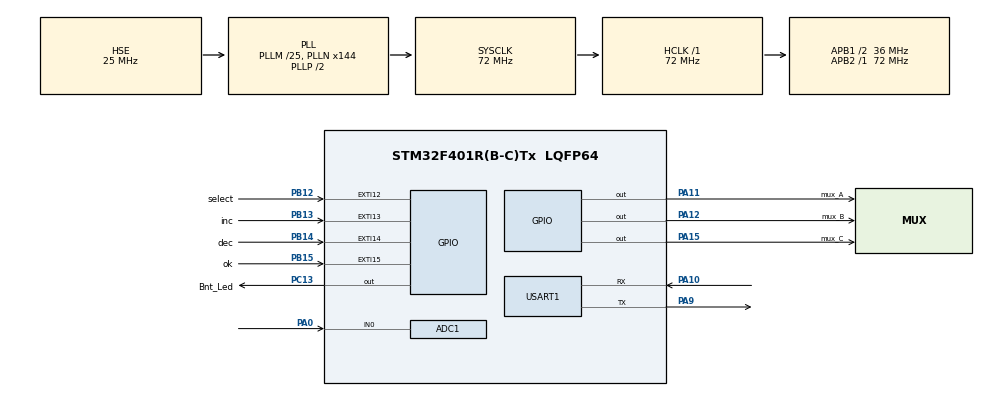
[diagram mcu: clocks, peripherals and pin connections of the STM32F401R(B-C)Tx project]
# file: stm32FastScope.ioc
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ADC1.Channel-2\#ChannelRegularConversion=ADC_CHANNEL_0
ADC1.Channel-3\#ChannelInjectedConversion=ADC_CHANNEL_0
ADC1.DMAContinuousRequests=ENABLE
ADC1.ExternalTrigConv=ADC_EXTERNALTRIGCONV_T3_TRGO
ADC1.InjNumberOfConversion=1
ADC1.InjectedOffset-3\#ChannelInjectedConversion=0
ADC1.InjectedRank-3\#ChannelInjectedConversion=1
ADC1.NbrOfConversion=1
ADC1.NbrOfConversionFlag=1
ADC1.Rank-2\#ChannelRegularConversion=1
ADC1.Resolution=ADC_RESOLUTION_8B
ADC1.SamplingTime-2\#ChannelRegularConversion=ADC_SAMPLETIME_3CYCLES
ADC1.SamplingTime-3\#ChannelInjectedConversion=ADC_SAMPLETIME_3CYCLES
ADC1.master=1
Dma.ADC1.0.Direction=DMA_PERIPH_TO_MEMORY
Dma.ADC1.0.FIFOMode=DMA_FIFOMODE_DISABLE
Dma.ADC1.0.Instance=DMA2_Stream0
Dma.ADC1.0.MemDataAlignment=DMA_MDATAALIGN_HALFWORD
Dma.ADC1.0.MemInc=DMA_MINC_ENABLE
Dma.ADC1.0.Mode=DMA_NORMAL
Dma.ADC1.0.PeriphDataAlignment=DMA_PDATAALIGN_HALFWORD
Dma.ADC1.0.PeriphInc=DMA_PINC_DISABLE
Dma.ADC1.0.Priority=DMA_PRIORITY_LOW
Dma.Request0=ADC1
Dma.Request1=USART1_TX
Dma.Request2=USART1_RX
Dma.USART1_RX.2.Direction=DMA_PERIPH_TO_MEMORY
Dma.USART1_RX.2.FIFOMode=DMA_FIFOMODE_DISABLE
Dma.USART1_RX.2.Instance=DMA2_Stream2
Dma.USART1_RX.2.MemDataAlignment=DMA_MDATAALIGN_BYTE
Dma.USART1_RX.2.MemInc=DMA_MINC_ENABLE
Dma.USART1_RX.2.Mode=DMA_CIRCULAR
Dma.USART1_RX.2.PeriphDataAlignment=DMA_PDATAALIGN_BYTE
Dma.USART1_RX.2.PeriphInc=DMA_PINC_DISABLE
Dma.USART1_RX.2.Priority=DMA_PRIORITY_LOW
Dma.USART1_TX.1.Direction=DMA_MEMORY_TO_PERIPH
Dma.USART1_TX.1.FIFOMode=DMA_FIFOMODE_DISABLE
Dma.USART1_TX.1.Instance=DMA2_Stream7
Dma.USART1_TX.1.MemDataAlignment=DMA_MDATAALIGN_BYTE
Dma.USART1_TX.1.MemInc=DMA_MINC_ENABLE
Dma.USART1_TX.1.Mode=DMA_CIRCULAR
Dma.USART1_TX.1.PeriphDataAlignment=DMA_PDATAALIGN_BYTE
Dma.USART1_TX.1.PeriphInc=DMA_PINC_DISABLE
Dma.USART1_TX.1.Priority=DMA_PRIORITY_LOW
Mcu.Family=STM32F4
Mcu.Name=STM32F401R(B-C)Tx
Mcu.Package=LQFP64
Mcu.UserConstants=Adc_prescaler,1;Adc_stop,1050
NVIC.DMA2_Stream0_IRQn=true\:0\:0\:false\:false\:true\:false\:true\:true
NVIC.DMA2_Stream2_IRQn=true\:0\:0\:false\:false\:true\:false\:true\:true
NVIC.DMA2_Stream7_IRQn=true\:0\:0\:false\:false\:true\:false\:true\:true
NVIC.EXTI15_10_IRQn=true\:0\:0\:false\:false\:true\:true\:true\:true
NVIC.PriorityGroup=NVIC_PRIORITYGROUP_4
NVIC.TIM3_IRQn=true\:0\:0\:false\:false\:true\:true\:true\:true
NVIC.TIM4_IRQn=true\:0\:0\:false\:false\:true\:true\:true\:true
PA0-WKUP.Signal=ADCx_IN0
PA10.Mode=Asynchronous
PA10.Signal=USART1_RX
PA11.GPIO_Label=mux_A
PA11.GPIO_PuPd=GPIO_PULLUP
PA11.Signal=GPIO_Output
PA12.GPIO_Label=mux_B
PA12.GPIO_PuPd=GPIO_PULLUP
PA12.Signal=GPIO_Output
PA15.GPIO_Label=mux_C
PA15.GPIO_PuPd=GPIO_PULLUP
PA15.Signal=GPIO_Output
PA9.Mode=Asynchronous
PA9.Signal=USART1_TX
PB12.GPIO_Label=select
PB12.GPIO_PuPd=GPIO_PULLUP
PB12.Signal=GPXTI12
PB13.GPIO_Label=inc
PB13.GPIO_PuPd=GPIO_PULLUP
PB13.Signal=GPXTI13
PB14.GPIO_Label=dec
PB14.GPIO_PuPd=GPIO_PULLUP
PB14.Signal=GPXTI14
PB15.GPIO_Label=ok
PB15.GPIO_PuPd=GPIO_PULLUP
PB15.Signal=GPXTI15
PC13-ANTI_TAMP.GPIO_Label=Bnt_Led
PC13-ANTI_TAMP.Signal=GPIO_Output
PH0\ -\ OSC_IN.Mode=HSE-External-Oscillator
PH0\ -\ OSC_IN.Signal=RCC_OSC_IN
PH1\ -\ OSC_OUT.Mode=HSE-External-Oscillator
PH1\ -\ OSC_OUT.Signal=RCC_OSC_OUT
ProjectManager.HeapSize=0x200
ProjectManager.StackSize=0x400
ProjectManager.TargetToolchain=STM32CubeIDE
RCC.48MHZClocksFreq_Value=36000000
RCC.AHBFreq_Value=72000000
RCC.APB1CLKDivider=RCC_HCLK_DIV2
RCC.APB1Freq_Value=36000000
RCC.APB1TimFreq_Value=72000000
RCC.APB2Freq_Value=72000000
RCC.APB2TimFreq_Value=72000000
RCC.CortexFreq_Value=72000000
RCC.HCLKFreq_Value=72000000
RCC.HSE_VALUE=25000000
RCC.HSI_VALUE=16000000
RCC.LSE_VALUE=32768
RCC.PLLM=25
RCC.PLLN=144
RCC.PLLSourceVirtual=RCC_PLLSOURCE_HSE
RCC.SYSCLKFreq_VALUE=72000000
RCC.SYSCLKSource=RCC_SYSCLKSOURCE_PLLCLK
RCC.VCOOutputFreq_Value=144000000
SH.ADCx_IN0.0=ADC1_IN0,IN0
TIM3.AutoReloadPreload=TIM_AUTORELOAD_PRELOAD_ENABLE
TIM3.ClockDivision=TIM_CLOCKDIVISION_DIV1
TIM3.Period=Adc_stop
TIM3.Prescaler=Adc_prescaler
TIM3.TIM_MasterOutputTrigger=TIM_TRGO_UPDATE
TIM3.TIM_MasterSlaveMode=TIM_MASTERSLAVEMODE_ENABLE
TIM4.Period=250
TIM4.Prescaler=20499
USART1.VirtualMode=VM_ASYNC
VP_TIM3_VS_ClockSourceINT.Mode=Internal
VP_TIM4_VS_ClockSourceINT.Mode=Internal
board=custom

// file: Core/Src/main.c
/* USER CODE BEGIN Header */
/**
 ******************************************************************************
 * @file           : main.c
 * @brief          : Main program body
 ******************************************************************************
 * @attention
 *
 * Copyright (c) 2023 STMicroelectronics.
 * All rights reserved.
 *
 * This software is licensed under terms that can be found in the LICENSE file
 * in the root directory of this software component.
 * If no LICENSE file comes with this software, it is provided AS-IS.
 *
 ******************************************************************************
 */
/* USER CODE END Header */
#include "main.h"

/* USER CODE BEGIN Includes */
//#include "defines.h"
/* USER CODE END Includes */

ADC_HandleTypeDef hadc1;
DMA_HandleTypeDef hdma_adc1;

TIM_HandleTypeDef htim3;
TIM_HandleTypeDef htim4;

UART_HandleTypeDef huart1;
DMA_HandleTypeDef hdma_usart1_tx;
DMA_HandleTypeDef hdma_usart1_rx;

void SystemClock_Config(void);
static void MX_GPIO_Init(void);
static void MX_DMA_Init(void);
static void MX_ADC1_Init(void);
static void MX_USART1_UART_Init(void);
static void MX_TIM3_Init(void);
static void MX_TIM4_Init(void);

int main(void)
{

  /* MCU Configuration--------------------------------------------------------*/

  /* Reset of all peripherals, Initializes the Flash interface and the Systick. */
  HAL_Init();

  /* Configure the system clock */
  SystemClock_Config();

  /* Initialize all configured peripherals */
  MX_GPIO_Init();
  MX_DMA_Init();
  MX_ADC1_Init();
  HAL_ADC1_Calibration_Start(&hadc1,0);
  MX_USART1_UART_Init();
  MX_TIM3_Init();
  MX_TIM4_Init();
  /* USER CODE BEGIN 2 */
	HAL_Delay(300);
//    HAL_ADCEx_Calibration_Start(&hadc1);
  /* USER CODE END 2 */

  /* Infinite loop */
  /* USER CODE BEGIN WHILE */
	//HAL_UART_Transmit(&huart1, "hellow", 7, 1000);
	while (1) {
    /* USER CODE END WHILE */

    /* USER CODE BEGIN 3 */
		mainScope();
	}
  /* USER CODE END 3 */
}

void SystemClock_Config(void)
{
  RCC_OscInitTypeDef RCC_OscInitStruct = {0};
  RCC_ClkInitTypeDef RCC_ClkInitStruct = {0};

  /** Configure the main internal regulator output voltage
  */
  __HAL_RCC_PWR_CLK_ENABLE();
  __HAL_PWR_VOLTAGESCALING_CONFIG(PWR_REGULATOR_VOLTAGE_SCALE2);

  /** Initializes the RCC Oscillators according to the specified parameters
  * in the RCC_OscInitTypeDef structure.
  */
  RCC_OscInitStruct.OscillatorType = RCC_OSCILLATORTYPE_HSE;
  RCC_OscInitStruct.HSEState = RCC_HSE_ON;
  RCC_OscInitStruct.PLL.PLLState = RCC_PLL_ON;
  RCC_OscInitStruct.PLL.PLLSource = RCC_PLLSOURCE_HSE;
  RCC_OscInitStruct.PLL.PLLM = 25;
  RCC_OscInitStruct.PLL.PLLN = 144;
  RCC_OscInitStruct.PLL.PLLP = RCC_PLLP_DIV2;
  RCC_OscInitStruct.PLL.PLLQ = 4;
  if (HAL_RCC_OscConfig(&RCC_OscInitStruct) != HAL_OK)
  {
    Error_Handler();
  }

  /** Initializes the CPU, AHB and APB buses clocks
  */
  RCC_ClkInitStruct.ClockType = RCC_CLOCKTYPE_HCLK|RCC_CLOCKTYPE_SYSCLK
                              |RCC_CLOCKTYPE_PCLK1|RCC_CLOCKTYPE_PCLK2;
  RCC_ClkInitStruct.SYSCLKSource = RCC_SYSCLKSOURCE_PLLCLK;
  RCC_ClkInitStruct.AHBCLKDivider = RCC_SYSCLK_DIV1;
  RCC_ClkInitStruct.APB1CLKDivider = RCC_HCLK_DIV2;
  RCC_ClkInitStruct.APB2CLKDivider = RCC_HCLK_DIV1;

  if (HAL_RCC_ClockConfig(&RCC_ClkInitStruct, FLASH_LATENCY_2) != HAL_OK)
  {
    Error_Handler();
  }
}

static void MX_ADC1_Init(void)
{

  ADC_ChannelConfTypeDef sConfig = {0};
  ADC_InjectionConfTypeDef sConfigInjected = {0};

  /** Configure the global features of the ADC (Clock, Resolution, Data Alignment and number of conversion)
  */
  hadc1.Instance = ADC1;
  hadc1.Init.ClockPrescaler = ADC_CLOCK_SYNC_PCLK_DIV2;
  hadc1.Init.Resolution = ADC_RESOLUTION_8B;
  hadc1.Init.ScanConvMode = DISABLE;
  hadc1.Init.ContinuousConvMode = DISABLE;
  hadc1.Init.DiscontinuousConvMode = DISABLE;
  hadc1.Init.ExternalTrigConvEdge = ADC_EXTERNALTRIGCONVEDGE_RISING;
  hadc1.Init.ExternalTrigConv = ADC_EXTERNALTRIGCONV_T3_TRGO;
  hadc1.Init.DataAlign = ADC_DATAALIGN_RIGHT;
  hadc1.Init.NbrOfConversion = 1;
  hadc1.Init.DMAContinuousRequests = ENABLE;
  hadc1.Init.EOCSelection = ADC_EOC_SINGLE_CONV;
  if (HAL_ADC_Init(&hadc1) != HAL_OK)
  {
    Error_Handler();
  }

  /** Configure for the selected ADC regular channel its corresponding rank in the sequencer and its sample time.
  */
  sConfig.Channel = ADC_CHANNEL_0;
  sConfig.Rank = 1;
  sConfig.SamplingTime = ADC_SAMPLETIME_3CYCLES;
  if (HAL_ADC_ConfigChannel(&hadc1, &sConfig) != HAL_OK)
  {
    Error_Handler();
  }

  /** Configures for the selected ADC injected channel its corresponding rank in the sequencer and its sample time
  */
  sConfigInjected.InjectedChannel = ADC_CHANNEL_0;
  sConfigInjected.InjectedRank = 1;
  sConfigInjected.InjectedNbrOfConversion = 1;
  sConfigInjected.InjectedSamplingTime = ADC_SAMPLETIME_3CYCLES;
  sConfigInjected.ExternalTrigInjecConvEdge = ADC_EXTERNALTRIGINJECCONVEDGE_NONE;
  sConfigInjected.ExternalTrigInjecConv = ADC_INJECTED_SOFTWARE_START;
  sConfigInjected.AutoInjectedConv = DISABLE;
  sConfigInjected.InjectedDiscontinuousConvMode = DISABLE;
  sConfigInjected.InjectedOffset = 0;
  if (HAL_ADCEx_InjectedConfigChannel(&hadc1, &sConfigInjected) != HAL_OK)
  {
    Error_Handler();
  }

}

static void MX_TIM3_Init(void)
{

  TIM_ClockConfigTypeDef sClockSourceConfig = {0};
  TIM_MasterConfigTypeDef sMasterConfig = {0};

  htim3.Instance = TIM3;
  htim3.Init.Prescaler = Adc_prescaler;
  htim3.Init.CounterMode = TIM_COUNTERMODE_UP;
  htim3.Init.Period = Adc_stop;
  htim3.Init.ClockDivision = TIM_CLOCKDIVISION_DIV1;
  htim3.Init.AutoReloadPreload = TIM_AUTORELOAD_PRELOAD_ENABLE;
  if (HAL_TIM_Base_Init(&htim3) != HAL_OK)
  {
    Error_Handler();
  }
  sClockSourceConfig.ClockSource = TIM_CLOCKSOURCE_INTERNAL;
  if (HAL_TIM_ConfigClockSource(&htim3, &sClockSourceConfig) != HAL_OK)
  {
    Error_Handler();
  }
  sMasterConfig.MasterOutputTrigger = TIM_TRGO_UPDATE;
  sMasterConfig.MasterSlaveMode = TIM_MASTERSLAVEMODE_ENABLE;
  if (HAL_TIMEx_MasterConfigSynchronization(&htim3, &sMasterConfig) != HAL_OK)
  {
    Error_Handler();
  }

}

static void MX_TIM4_Init(void)
{

  TIM_ClockConfigTypeDef sClockSourceConfig = {0};
  TIM_MasterConfigTypeDef sMasterConfig = {0};

  htim4.Instance = TIM4;
  htim4.Init.Prescaler = 20499;
  htim4.Init.CounterMode = TIM_COUNTERMODE_UP;
  htim4.Init.Period = 250;
  htim4.Init.ClockDivision = TIM_CLOCKDIVISION_DIV1;
  htim4.Init.AutoReloadPreload = TIM_AUTORELOAD_PRELOAD_DISABLE;
  if (HAL_TIM_Base_Init(&htim4) != HAL_OK)
  {
    Error_Handler();
  }
  sClockSourceConfig.ClockSource = TIM_CLOCKSOURCE_INTERNAL;
  if (HAL_TIM_ConfigClockSource(&htim4, &sClockSourceConfig) != HAL_OK)
  {
    Error_Handler();
  }
  sMasterConfig.MasterOutputTrigger = TIM_TRGO_RESET;
  sMasterConfig.MasterSlaveMode = TIM_MASTERSLAVEMODE_DISABLE;
  if (HAL_TIMEx_MasterConfigSynchronization(&htim4, &sMasterConfig) != HAL_OK)
  {
    Error_Handler();
  }

}

static void MX_USART1_UART_Init(void)
{

  huart1.Instance = USART1;
  huart1.Init.BaudRate = 115200;
  huart1.Init.WordLength = UART_WORDLENGTH_8B;
  huart1.Init.StopBits = UART_STOPBITS_1;
  huart1.Init.Parity = UART_PARITY_NONE;
  huart1.Init.Mode = UART_MODE_TX_RX;
  huart1.Init.HwFlowCtl = UART_HWCONTROL_NONE;
  huart1.Init.OverSampling = UART_OVERSAMPLING_16;
  if (HAL_UART_Init(&huart1) != HAL_OK)
  {
    Error_Handler();
  }

}

static void MX_DMA_Init(void)
{

  /* DMA controller clock enable */
  __HAL_RCC_DMA2_CLK_ENABLE();

  /* DMA interrupt init */
  /* DMA2_Stream0_IRQn interrupt configuration */
  HAL_NVIC_SetPriority(DMA2_Stream0_IRQn, 0, 0);
  HAL_NVIC_EnableIRQ(DMA2_Stream0_IRQn);
  /* DMA2_Stream2_IRQn interrupt configuration */
  HAL_NVIC_SetPriority(DMA2_Stream2_IRQn, 0, 0);
  HAL_NVIC_EnableIRQ(DMA2_Stream2_IRQn);
  /* DMA2_Stream7_IRQn interrupt configuration */
  HAL_NVIC_SetPriority(DMA2_Stream7_IRQn, 0, 0);
  HAL_NVIC_EnableIRQ(DMA2_Stream7_IRQn);

}

static void MX_GPIO_Init(void)
{
  GPIO_InitTypeDef GPIO_InitStruct = {0};

  /* GPIO Ports Clock Enable */
  __HAL_RCC_GPIOC_CLK_ENABLE();
  __HAL_RCC_GPIOH_CLK_ENABLE();
  __HAL_RCC_GPIOA_CLK_ENABLE();
  __HAL_RCC_GPIOB_CLK_ENABLE();

  /*Configure GPIO pin Output Level */
  HAL_GPIO_WritePin(Bnt_Led_GPIO_Port, Bnt_Led_Pin, GPIO_PIN_RESET);

  /*Configure GPIO pin Output Level */
  HAL_GPIO_WritePin(GPIOA, mux_A_Pin|mux_B_Pin|mux_C_Pin, GPIO_PIN_RESET);

  /*Configure GPIO pin : Bnt_Led_Pin */
  GPIO_InitStruct.Pin = Bnt_Led_Pin;
  GPIO_InitStruct.Mode = GPIO_MODE_OUTPUT_PP;
  GPIO_InitStruct.Pull = GPIO_NOPULL;
  GPIO_InitStruct.Speed = GPIO_SPEED_FREQ_LOW;
  HAL_GPIO_Init(Bnt_Led_GPIO_Port, &GPIO_InitStruct);

  /*Configure GPIO pins : select_Pin inc_Pin dec_Pin ok_Pin */
  GPIO_InitStruct.Pin = select_Pin|inc_Pin|dec_Pin|ok_Pin;
  GPIO_InitStruct.Mode = GPIO_MODE_IT_RISING;
  GPIO_InitStruct.Pull = GPIO_PULLUP;
  HAL_GPIO_Init(GPIOB, &GPIO_InitStruct);

  /*Configure GPIO pins : mux_A_Pin mux_B_Pin mux_C_Pin */
  GPIO_InitStruct.Pin = mux_A_Pin|mux_B_Pin|mux_C_Pin;
  GPIO_InitStruct.Mode = GPIO_MODE_OUTPUT_PP;
  GPIO_InitStruct.Pull = GPIO_PULLUP;
  GPIO_InitStruct.Speed = GPIO_SPEED_FREQ_LOW;
  HAL_GPIO_Init(GPIOA, &GPIO_InitStruct);

  /* EXTI interrupt init*/
  HAL_NVIC_SetPriority(EXTI15_10_IRQn, 0, 0);
  HAL_NVIC_EnableIRQ(EXTI15_10_IRQn);

}

void Error_Handler(void)
{
	__disable_irq();
	while (1) {
	}
}
